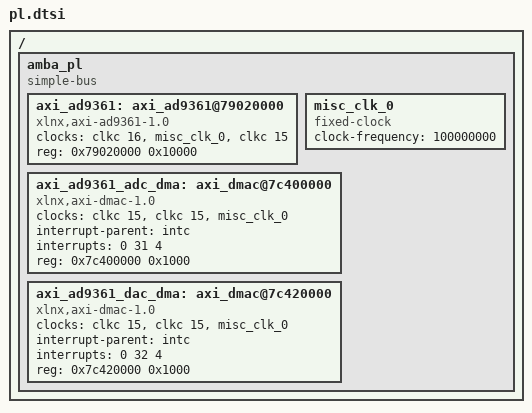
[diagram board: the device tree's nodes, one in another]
/*
 * CAUTION: This file is automatically generated by Xilinx.
 * Version:  
 * Today is: Sun Jan  9 16:56:18 2022
 */


/ {
	amba_pl: amba_pl {
		#address-cells = <1>;
		#size-cells = <1>;
		compatible = "simple-bus";
		ranges ;
		axi_ad9361: axi_ad9361@79020000 {
			clock-names = "delay_clk", "clk", "s_axi_aclk";
			clocks = <&clkc 16>, <&misc_clk_0>, <&clkc 15>;
			compatible = "xlnx,axi-ad9361-1.0";
			reg = <0x79020000 0x10000>;
		};
		misc_clk_0: misc_clk_0 {
			#clock-cells = <0>;
			clock-frequency = <100000000>;
			compatible = "fixed-clock";
		};
		axi_ad9361_adc_dma: axi_dmac@7c400000 {
			clock-names = "s_axi_aclk", "m_dest_axi_aclk", "fifo_wr_clk";
			clocks = <&clkc 15>, <&clkc 15>, <&misc_clk_0>;
			compatible = "xlnx,axi-dmac-1.0";
			interrupt-names = "irq";
			interrupt-parent = <&intc>;
			interrupts = <0 31 4>;
			reg = <0x7c400000 0x1000>;
		};
		axi_ad9361_dac_dma: axi_dmac@7c420000 {
			clock-names = "s_axi_aclk", "m_src_axi_aclk", "m_axis_aclk";
			clocks = <&clkc 15>, <&clkc 15>, <&misc_clk_0>;
			compatible = "xlnx,axi-dmac-1.0";
			interrupt-names = "irq";
			interrupt-parent = <&intc>;
			interrupts = <0 32 4>;
			reg = <0x7c420000 0x1000>;
		};
	};
};
